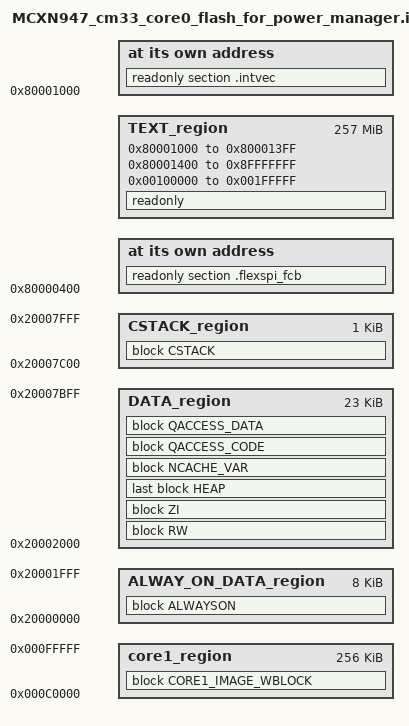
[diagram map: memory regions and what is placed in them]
/*
 * Copyright 2024 NXP
 *
 * SPDX-License-Identifier: BSD-3-Clause
 */

/* Stack and Heap Sizes */
if (isdefinedsymbol(__stack_size__)) {
  define symbol __size_cstack__        = __stack_size__;
} else {
  define symbol __size_cstack__        = 0x0400;
}

if (isdefinedsymbol(__heap_size__)) {
  define symbol __size_heap__          = __heap_size__;
} else {
  define symbol __size_heap__          = 0x0400;
}

if (isdefinedsymbol(__qspi_xip__)) {
  define symbol m_interrupts_start               = 0x80001000;
  define symbol m_interrupts_end                 = 0x800013FF;

  define symbol m_text_start                     = 0x80001400;
  define symbol m_text_end                       = 0x8FFFFFFF;
} else {
  define symbol m_interrupts_start               = 0x00000000;
  define symbol m_interrupts_end                 = 0x000003FF;

  define symbol m_text_start                     = 0x00000400;
  define symbol m_text_end                       = 0x000BFFFF;
}

define symbol m_boot_flash_conf_start          = 0x80000400;

define symbol m_flash1_start                   = 0x00100000;
define symbol m_flash1_end                     = 0x001FFFFF;

define symbol m_sramx_start                    = 0x04000000;
define symbol m_sramx_end                      = 0x04017FFF;

define exported symbol core1_image_start       = 0x000C0000;
define exported symbol core1_image_end         = 0x000FFFFF;

define symbol m_data_start                     = 0x20002000;
define symbol m_data_end                       = 0x20007FFF;

define symbol m_data_always_on_start            = 0x20000000;
define symbol m_data_always_on_end              = 0x20001FFF;

define memory mem with size = 4G;

if (isdefinedsymbol(__qspi_xip__)) {
  define region TEXT_region             = mem:[from m_interrupts_start to m_interrupts_end]
                                      | mem:[from m_text_start to m_text_end];
} else {
  define region TEXT_region             = mem:[from m_interrupts_start to m_interrupts_end]
                                      | mem:[from m_text_start to m_text_end]
                                      | mem:[from m_flash1_start to m_flash1_end];
}
define region DATA_region = mem:[from m_data_start to m_data_end-__size_cstack__];
define region CSTACK_region = mem:[from m_data_end-__size_cstack__+1 to m_data_end];
define region ALWAY_ON_DATA_region    = mem:[from m_data_always_on_start to m_data_always_on_end];

define block CSTACK        with alignment = 8, size = __size_cstack__   { };
define block HEAP          with alignment = 8, size = __size_heap__     { };
define block RW            { readwrite };
define block ZI            { zi };
define block NCACHE_VAR    { section NonCacheable , section NonCacheable.init };
define block QACCESS_CODE  { section CodeQuickAccess };
define block QACCESS_DATA  { section DataQuickAccess };
define block ALWAYSON      { section AlwaysOnData, section AlwaysOnData.init};

define region core1_region = mem:[from core1_image_start to core1_image_end];
define block CORE1_IMAGE_WBLOCK          { section  __core1_image };

initialize by copy { readwrite, section .textrw, section CodeQuickAccess, section DataQuickAccess };

if (isdefinedsymbol(__USE_DLIB_PERTHREAD))
{
  /* Required in a multi-threaded application */
  initialize by copy with packing = none { section __DLIB_PERTHREAD };
}

keep{section .flexspi_fcb };
place at address mem: m_boot_flash_conf_start { readonly section .flexspi_fcb };
place at address mem: m_interrupts_start      { readonly section .intvec };
place in TEXT_region                          { readonly };
place in DATA_region                          { block RW };
place in DATA_region                          { block ZI };
place in DATA_region                          { last block HEAP };
place in CSTACK_region                        { block CSTACK };
place in DATA_region                          { block NCACHE_VAR };
place in DATA_region                          { block QACCESS_CODE };
place in DATA_region                          { block QACCESS_DATA };
place in core1_region                         { block CORE1_IMAGE_WBLOCK };
place in ALWAY_ON_DATA_region                 { block ALWAYSON };
